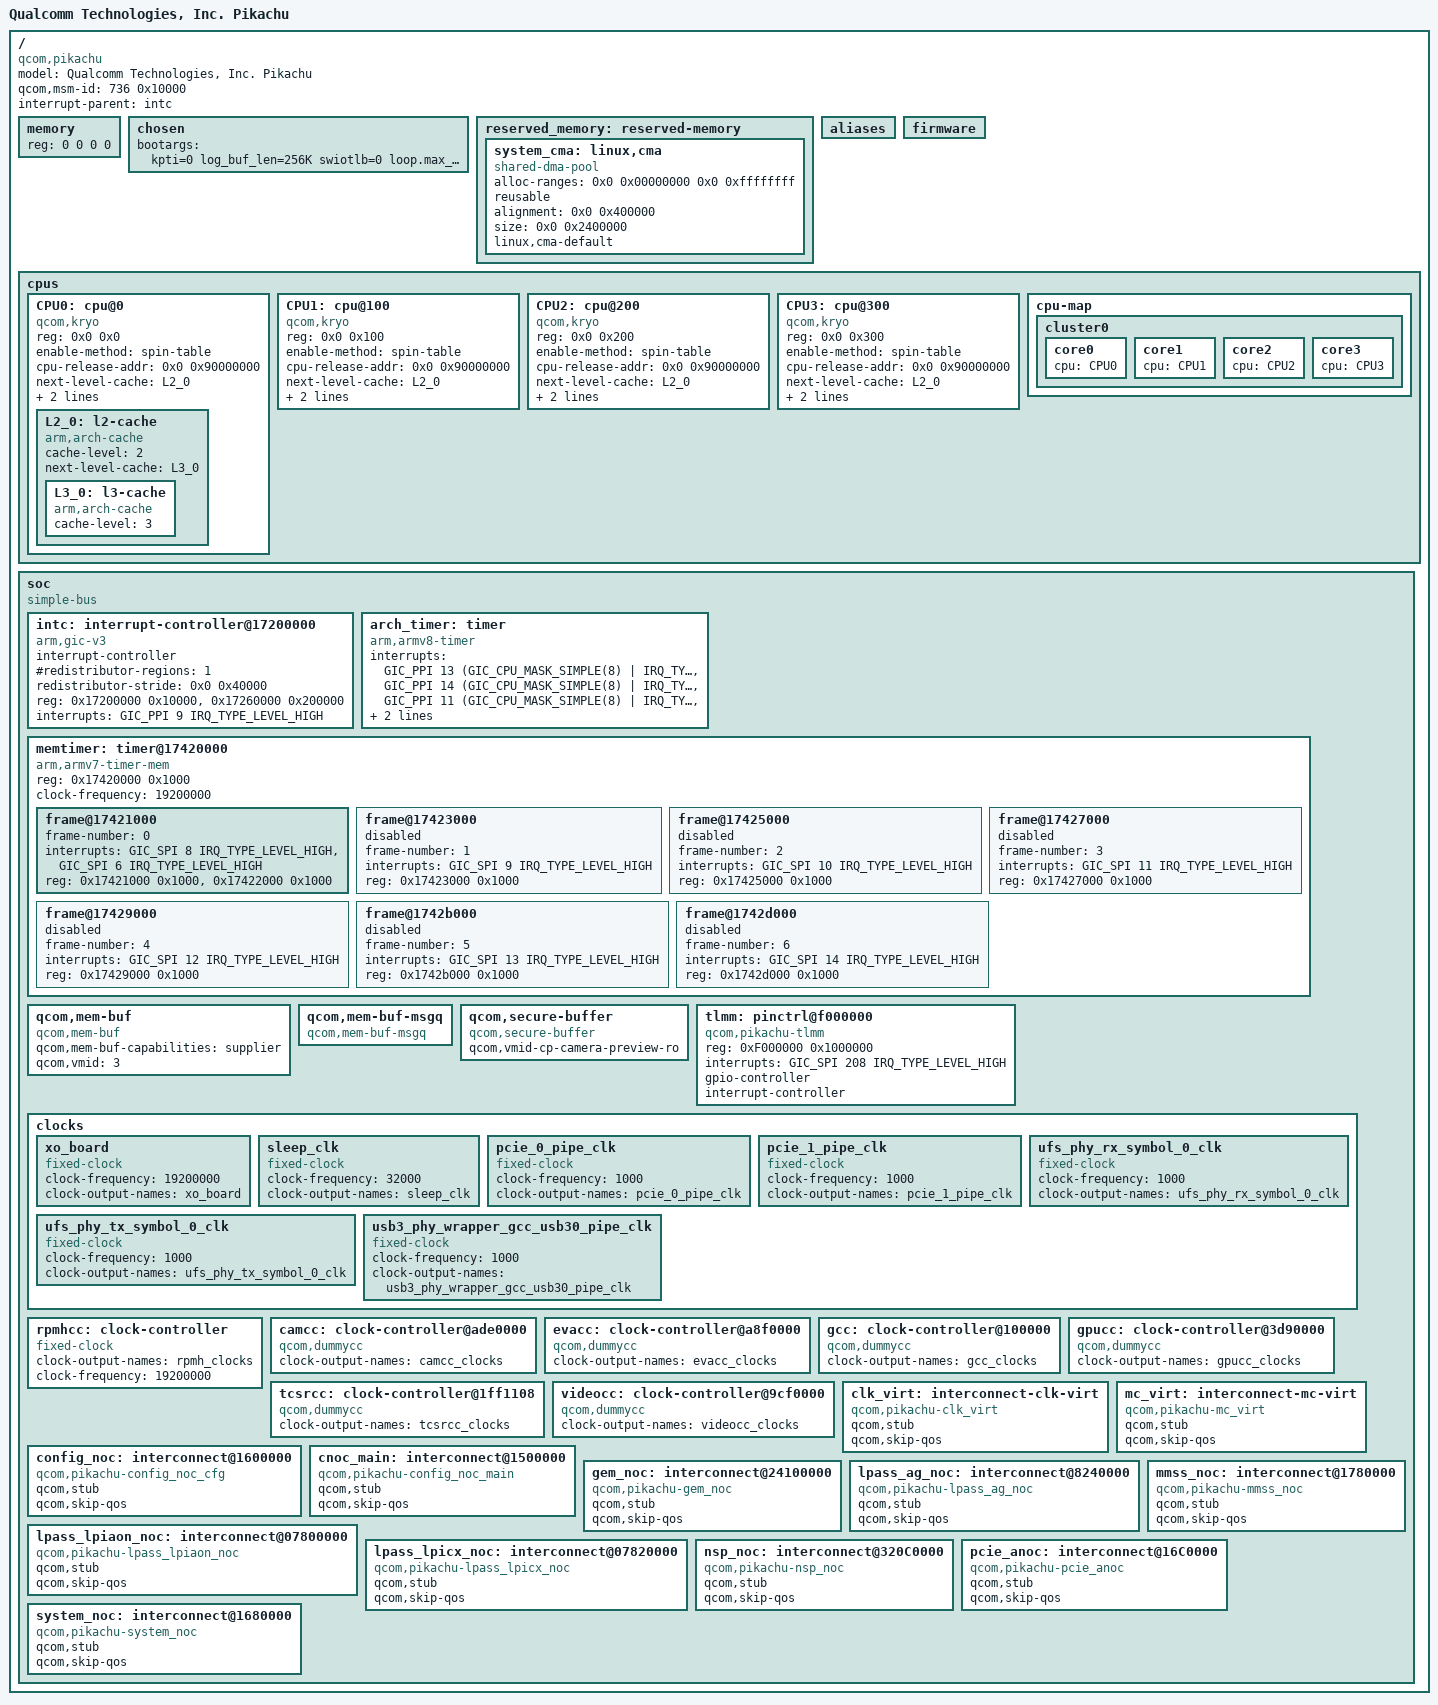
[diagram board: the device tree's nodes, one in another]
// SPDX-License-Identifier: BSD-3-Clause
/*
 * Copyright (c) Qualcomm Technologies, Inc. and/or its subsidiaries.
 */

#include <dt-bindings/interrupt-controller/arm-gic.h>
#include <dt-bindings/clock/qcom,rpmh.h>
#include <dt-bindings/clock/qcom,pikachu-camcc.h>
#include <dt-bindings/clock/qcom,pikachu-evacc.h>
#include <dt-bindings/clock/qcom,pikachu-gcc.h>
#include <dt-bindings/clock/qcom,pikachu-gpucc.h>
#include <dt-bindings/clock/qcom,pikachu-tcsrcc.h>
#include <dt-bindings/clock/qcom,pikachu-videocc.h>
#include <dt-bindings/regulator/qcom,rpmh-regulator-levels.h>
/ {
	model = "Qualcomm Technologies, Inc. Pikachu";
	compatible = "qcom,pikachu";
	qcom,msm-id = <736 0x10000>;
	interrupt-parent = <&intc>;

	#address-cells = <2>;
	#size-cells = <2>;
	memory { device_type = "memory"; reg = <0 0 0 0>; };

	chosen: chosen {
		bootargs = "kpti=0 log_buf_len=256K swiotlb=0 loop.max_part=7 loglevel=8 swiotlb=0 kasan=off cgroup_disable=pressure cgroup.memory=nokmem,nosocket disable_dma32=on restrict_cma_redirect=false";
	};

	reserved_memory: reserved-memory {};

	aliases { };

	firmware: firmware {};

	cpus {
		#address-cells = <2>;
		#size-cells = <0>;

		CPU0: cpu@0 {
			device_type = "cpu";
			compatible = "qcom,kryo";
			reg = <0x0 0x0>;
			enable-method = "spin-table";
			cpu-release-addr = <0x0 0x90000000>;
			next-level-cache = <&L2_0>;
			capacity-dmips-mhz = <1024>;
			dynamic-power-coefficient = <100>;
			L2_0: l2-cache {
				compatible = "arm,arch-cache";
				cache-level = <2>;
				next-level-cache = <&L3_0>;

				L3_0: l3-cache {
					compatible = "arm,arch-cache";
					cache-level = <3>;
				};
			};
		};

		CPU1: cpu@100 {
			device_type = "cpu";
			compatible = "qcom,kryo";
			reg = <0x0 0x100>;
			enable-method = "spin-table";
			cpu-release-addr = <0x0 0x90000000>;
			next-level-cache = <&L2_0>;
			capacity-dmips-mhz = <1024>;
			dynamic-power-coefficient = <100>;
		};

		CPU2: cpu@200 {
			device_type = "cpu";
			compatible = "qcom,kryo";
			reg = <0x0 0x200>;
			enable-method = "spin-table";
			cpu-release-addr = <0x0 0x90000000>;
			next-level-cache = <&L2_0>;
			capacity-dmips-mhz = <1024>;
			dynamic-power-coefficient = <100>;
		};

		CPU3: cpu@300 {
			device_type = "cpu";
			compatible = "qcom,kryo";
			reg = <0x0 0x300>;
			enable-method = "spin-table";
			cpu-release-addr = <0x0 0x90000000>;
			next-level-cache = <&L2_0>;
			capacity-dmips-mhz = <1024>;
			dynamic-power-coefficient = <100>;
		};

		cpu-map {
			cluster0 {
				core0 {
					cpu = <&CPU0>;
				};

				core1 {
					cpu = <&CPU1>;
				};

				core2 {
					cpu = <&CPU2>;
				};

				core3 {
					cpu = <&CPU3>;
				};
			};
		};
	};

	soc: soc { };

};

&soc {
	#address-cells = <1>;
	#size-cells = <1>;

	ranges = <0 0 0 0xffffffff>;
	compatible = "simple-bus";

	intc: interrupt-controller@17200000 {
		compatible = "arm,gic-v3";
		#interrupt-cells = <3>;
		interrupt-controller;
		#redistributor-regions = <1>;
		redistributor-stride = <0x0 0x40000>;
		reg = <0x17200000 0x10000>,       /* GICD */
		     <0x17260000 0x200000>;       /* GICR * 8 */
		interrupts = <GIC_PPI 9 IRQ_TYPE_LEVEL_HIGH>;
	};

	arch_timer: timer {
		compatible = "arm,armv8-timer";
		interrupts = <GIC_PPI 13 (GIC_CPU_MASK_SIMPLE(8) | IRQ_TYPE_LEVEL_LOW)>,
			     <GIC_PPI 14 (GIC_CPU_MASK_SIMPLE(8) | IRQ_TYPE_LEVEL_LOW)>,
			     <GIC_PPI 11 (GIC_CPU_MASK_SIMPLE(8) | IRQ_TYPE_LEVEL_LOW)>,
			     <GIC_PPI 12 (GIC_CPU_MASK_SIMPLE(8) | IRQ_TYPE_LEVEL_LOW)>;
		clock-frequency = <19200000>;
	};

	memtimer: timer@17420000 {
		#address-cells = <1>;
		#size-cells = <1>;
		ranges;
		compatible = "arm,armv7-timer-mem";
		reg = <0x17420000 0x1000>;
		clock-frequency = <19200000>;

		frame@17421000 {
			frame-number = <0>;
			interrupts = <GIC_SPI 8 IRQ_TYPE_LEVEL_HIGH>,
				     <GIC_SPI 6 IRQ_TYPE_LEVEL_HIGH>;
			reg = <0x17421000 0x1000>,
			      <0x17422000 0x1000>;
		};

		frame@17423000 {
			frame-number = <1>;
			interrupts = <GIC_SPI 9 IRQ_TYPE_LEVEL_HIGH>;
			reg = <0x17423000 0x1000>;
			status = "disabled";
		};

		frame@17425000 {
			frame-number = <2>;
			interrupts = <GIC_SPI 10 IRQ_TYPE_LEVEL_HIGH>;
			reg = <0x17425000 0x1000>;
			status = "disabled";
		};

		frame@17427000 {
			frame-number = <3>;
			interrupts = <GIC_SPI 11 IRQ_TYPE_LEVEL_HIGH>;
			reg = <0x17427000 0x1000>;
			status = "disabled";
		};

		frame@17429000 {
			frame-number = <4>;
			interrupts = <GIC_SPI 12 IRQ_TYPE_LEVEL_HIGH>;
			reg = <0x17429000 0x1000>;
			status = "disabled";
		};

		frame@1742b000 {
			frame-number = <5>;
			interrupts = <GIC_SPI 13 IRQ_TYPE_LEVEL_HIGH>;
			reg = <0x1742b000 0x1000>;
			status = "disabled";
		};

		frame@1742d000 {
			frame-number = <6>;
			interrupts = <GIC_SPI 14 IRQ_TYPE_LEVEL_HIGH>;
			reg = <0x1742d000 0x1000>;
			status = "disabled";
		};
	};

	qcom,mem-buf {
		compatible = "qcom,mem-buf";
		qcom,mem-buf-capabilities = "supplier";
		qcom,vmid = <3>;
	};

	qcom,mem-buf-msgq {
		compatible = "qcom,mem-buf-msgq";
	};

	qcom,secure-buffer {
		compatible = "qcom,secure-buffer";
		qcom,vmid-cp-camera-preview-ro;
	};

	tlmm: pinctrl@f000000 {
		compatible = "qcom,pikachu-tlmm";
		reg = <0xF000000 0x1000000>;
		interrupts = <GIC_SPI 208 IRQ_TYPE_LEVEL_HIGH>;
		gpio-controller;
		#gpio-cells = <2>;
		interrupt-controller;
		#interrupt-cells = <2>;
	};

	clocks {
		xo_board: xo_board {
			compatible = "fixed-clock";
			clock-frequency = <19200000>;
			clock-output-names = "xo_board";
			#clock-cells = <0>;
		};

		sleep_clk: sleep_clk {
			compatible = "fixed-clock";
			clock-frequency = <32000>;
			clock-output-names = "sleep_clk";
			#clock-cells = <0>;
		};

		pcie_0_pipe_clk: pcie_0_pipe_clk {
			compatible = "fixed-clock";
			clock-frequency = <1000>;
			clock-output-names = "pcie_0_pipe_clk";
			#clock-cells = <0>;
		};

		pcie_1_pipe_clk: pcie_1_pipe_clk {
			compatible = "fixed-clock";
			clock-frequency = <1000>;
			clock-output-names = "pcie_1_pipe_clk";
			#clock-cells = <0>;
		};

		ufs_phy_rx_symbol_0_clk: ufs_phy_rx_symbol_0_clk {
			compatible = "fixed-clock";
			clock-frequency = <1000>;
			clock-output-names = "ufs_phy_rx_symbol_0_clk";
			#clock-cells = <0>;
		};

		ufs_phy_tx_symbol_0_clk: ufs_phy_tx_symbol_0_clk {
			compatible = "fixed-clock";
			clock-frequency = <1000>;
			clock-output-names = "ufs_phy_tx_symbol_0_clk";
			#clock-cells = <0>;
		};

		usb3_phy_wrapper_gcc_usb30_pipe_clk: usb3_phy_wrapper_gcc_usb30_pipe_clk {
			compatible = "fixed-clock";
			clock-frequency = <1000>;
			clock-output-names = "usb3_phy_wrapper_gcc_usb30_pipe_clk";
			#clock-cells = <0>;
		};
	};

	rpmhcc: clock-controller {
		compatible = "fixed-clock";
		clock-output-names = "rpmh_clocks";
		clock-frequency = <19200000>;
		#clock-cells = <1>;
	};

	camcc: clock-controller@ade0000 {
		compatible = "qcom,dummycc";
		clock-output-names = "camcc_clocks";
		#clock-cells = <1>;
		#reset-cells = <1>;
		#power-domain-cells = <1>;
	};

	evacc: clock-controller@a8f0000 {
		compatible = "qcom,dummycc";
		clock-output-names = "evacc_clocks";
		#clock-cells = <1>;
		#reset-cells = <1>;
		#power-domain-cells = <1>;
	};

	gcc: clock-controller@100000 {
		compatible = "qcom,dummycc";
		clock-output-names = "gcc_clocks";
		#clock-cells = <1>;
		#reset-cells = <1>;
		#power-domain-cells = <1>;
	};

	gpucc: clock-controller@3d90000 {
		compatible = "qcom,dummycc";
		clock-output-names = "gpucc_clocks";
		#clock-cells = <1>;
		#reset-cells = <1>;
		#power-domain-cells = <1>;
	};

	tcsrcc: clock-controller@1ff1108 {
		compatible = "qcom,dummycc";
		clock-output-names = "tcsrcc_clocks";
		#clock-cells = <1>;
		#reset-cells = <1>;
	};

	videocc: clock-controller@9cf0000 {
		compatible = "qcom,dummycc";
		clock-output-names = "videocc_clocks";
		#clock-cells = <1>;
		#reset-cells = <1>;
		#power-domain-cells = <1>;
	};

	clk_virt: interconnect-clk-virt {
		compatible = "qcom,pikachu-clk_virt";
		#interconnect-cells = <1>;
		qcom,stub;
		qcom,skip-qos;
	};

	mc_virt: interconnect-mc-virt {
		compatible = "qcom,pikachu-mc_virt";
		#interconnect-cells = <1>;
		qcom,stub;
		qcom,skip-qos;
	};

	config_noc: interconnect@1600000 {
		compatible = "qcom,pikachu-config_noc_cfg";
		#interconnect-cells = <1>;
		qcom,stub;
		qcom,skip-qos;
	};

	cnoc_main: interconnect@1500000 {
		compatible = "qcom,pikachu-config_noc_main";
		#interconnect-cells = <1>;
		qcom,stub;
		qcom,skip-qos;
	};

	gem_noc: interconnect@24100000 {
		compatible = "qcom,pikachu-gem_noc";
		#interconnect-cells = <1>;
		qcom,stub;
		qcom,skip-qos;
	};

	lpass_ag_noc: interconnect@8240000 {
		compatible = "qcom,pikachu-lpass_ag_noc";
		#interconnect-cells = <1>;
		qcom,stub;
		qcom,skip-qos;
	};

	lpass_lpiaon_noc: interconnect@07800000 {
		compatible = "qcom,pikachu-lpass_lpiaon_noc";
		#interconnect-cells = <1>;
		qcom,stub;
		qcom,skip-qos;
	};

	lpass_lpicx_noc: interconnect@07820000 {
		compatible = "qcom,pikachu-lpass_lpicx_noc";
		#interconnect-cells = <1>;
		qcom,stub;
		qcom,skip-qos;
	};

	mmss_noc: interconnect@1780000 {
		compatible = "qcom,pikachu-mmss_noc";
		#interconnect-cells = <1>;
		qcom,stub;
		qcom,skip-qos;
	};

	nsp_noc: interconnect@320C0000 {
		compatible = "qcom,pikachu-nsp_noc";
		#interconnect-cells = <1>;
		qcom,stub;
		qcom,skip-qos;
	};

	pcie_anoc: interconnect@16C0000 {
		compatible = "qcom,pikachu-pcie_anoc";
		#interconnect-cells = <1>;
		qcom,stub;
		qcom,skip-qos;
	};

	system_noc: interconnect@1680000 {
		compatible = "qcom,pikachu-system_noc";
		#interconnect-cells = <1>;
		qcom,stub;
		qcom,skip-qos;
	};

};

#include "pikachu-reserved-memory.dtsi"

&reserved_memory {
	#address-cells = <2>;
	#size-cells = <2>;
	ranges;

	/* global autoconfigured region for contiguous allocations */
	system_cma: linux,cma {
		compatible = "shared-dma-pool";
		alloc-ranges = <0x0 0x00000000 0x0 0xffffffff>;
		reusable;
		alignment = <0x0 0x400000>;
		size = <0x0 0x2400000>;
		linux,cma-default;
	};

};

#include "msm-arm-smmu-pikachu.dtsi"
#include "pikachu-pinctrl.dtsi"
#include "pikachu-stub-regulators.dtsi"
